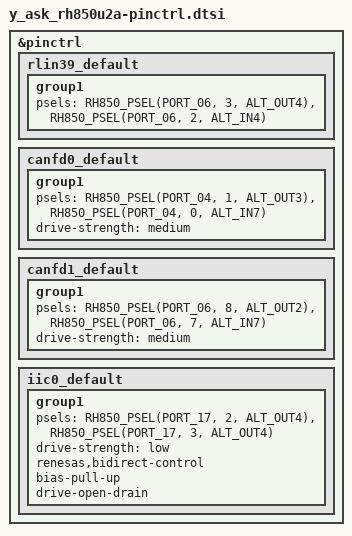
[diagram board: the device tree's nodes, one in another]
/*
 * Copyright (c) 2026 Renesas Electronics Corporation
 * SPDX-License-Identifier: Apache-2.0
 */

#include <dt-bindings/pinctrl/renesas/pinctrl-rh850u2a.h>

&pinctrl {
	rlin39_default: rlin39_default {
		group1 {
			psels = <RH850_PSEL(PORT_06, 3, ALT_OUT4)>,
				<RH850_PSEL(PORT_06, 2, ALT_IN4)>;
		};
	};

	canfd0_default: canfd0_default {
		group1 {
			psels = <RH850_PSEL(PORT_04, 1, ALT_OUT3)>,	/* TX */
				<RH850_PSEL(PORT_04, 0, ALT_IN7)>;	/* RX */
			drive-strength = "medium";
		};
	};

	canfd1_default: canfd1_default {
		group1 {
			psels = <RH850_PSEL(PORT_06, 8, ALT_OUT2)>,	/* TX */
				<RH850_PSEL(PORT_06, 7, ALT_IN7)>;	/* RX */
			drive-strength = "medium";
		};
	};

	iic0_default: iic0_default {
		group1 {
			psels = <RH850_PSEL(PORT_17, 2, ALT_OUT4)>,
				<RH850_PSEL(PORT_17, 3, ALT_OUT4)>;
			drive-strength = "low";
			renesas,bidirect-control;
			bias-pull-up;
			drive-open-drain;
		};
	};
};
